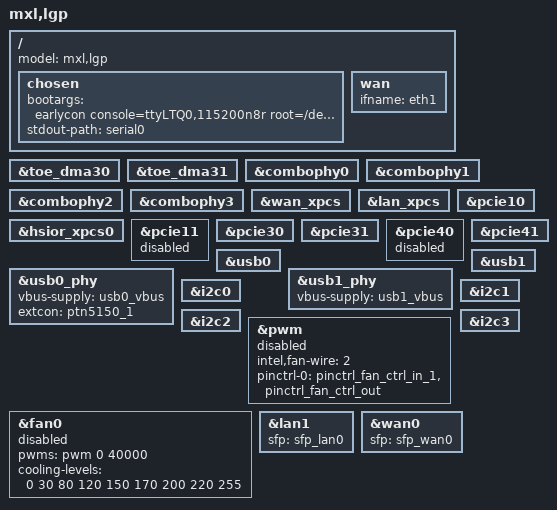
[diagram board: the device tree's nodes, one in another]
// SPDX-License-Identifier: GPL-2.0
/*
 * Copyright (C) 2020-2022 MaxLinear, Inc.
 * Copyright (C) 2019-2020 Intel Corporation.
 *
 * This program is free software; you can redistribute it and/or modify it
 * under the terms of the GNU General Public License, as published by the Free
 * Software Foundation; either version 2 of the License, or (at your option)
 * any later version.
 *
 * This program is distributed in the hope that it will be useful, but WITHOUT
 * ANY WARRANTY; without even the implied warranty of MERCHANTABILITY or
 * FITNESS FOR A PARTICULAR PURPOSE.
 * See the GNU General Public License for more details.
 *
 * You should have received a copy of the GNU General Public License along
 * with this program; if not, see <http://www.gnu.org/licenses/>.
 */

/dts-v1/;
#include <dt-bindings/thermal/thermal.h>

#include "lgp.dtsi"
#include "lgp_thermal_no_fan_big_heatsink.dtsi"
#include "voice.dtsi"

/ {
	model = "mxl,lgp";

	chosen {
		/* ramfs */
		bootargs = "earlycon console=ttyLTQ0,115200n8r root=/dev/ram init=/init maxcpus=4 initcall_debug=0 clk_ignore_unused loglevel=8";
		stdout-path = "serial0";
	};

	wan {
		ifname = "eth1";
	};
};

&toe_dma30 {
	status = "okay";
};

&toe_dma31 {
	status = "okay";
};

/* combo PHY setting */
/* combo phy 0 */
&combophy0 {
	status = "okay";
};

/* combo phy 1 */
&combophy1 {
	status = "okay";
};

/* combo phy 2 */
&combophy2 {
	status = "okay";
};

/* combo phy 3 */
&combophy3 {
	status = "okay";
};

/* XPCS setting */
&wan_xpcs {
	status = "okay";
};

&lan_xpcs {
	status = "okay";
};

&hsior_xpcs0 {
	status = "okay";
};

 /* PCIe */
&pcie10 { /* WIFI */
	status = "okay";
};

&pcie11 { /* M2_KeyB */
	status = "disabled";
};

&pcie30 { /* WIFI */
	status = "okay";
};

&pcie31 { /* DSL */
	status = "okay";
};

&pcie40 { /* M2_KeyM */
	status = "disabled";
};

&pcie41 { /* wifi */
	status = "okay";
};

&usb0_phy {
	status = "okay";
	vbus-supply = <&usb0_vbus>;
	extcon = <&ptn5150_1>;
};

&usb0 {
	status = "okay";
};

&usb1_phy {
	status = "okay";
	vbus-supply = <&usb1_vbus>;
};

&usb1 {
	status = "okay";
};

&i2c0 {
	status = "okay";
};

&i2c1 {
	status = "okay";
};

&i2c2 {
	status = "okay";
};

&i2c3 {
	status = "okay";
};

&pwm {
	status = "disabled";
	intel,fan-wire = <2>;
	pinctrl-names = "default";
	pinctrl-0 = <&pinctrl_fan_ctrl_in_1 &pinctrl_fan_ctrl_out>;
};

&fan0 {
	status = "disabled";
	pwms = <&pwm 0 40000>;
	#cooling-cells = <2>;
	cooling-levels = <0 30 80 120 150 170 200 220 255>;
};

&lan1 {
	sfp = <&sfp_lan0>;
};

&wan0 {
	sfp = <&sfp_wan0>;
};
